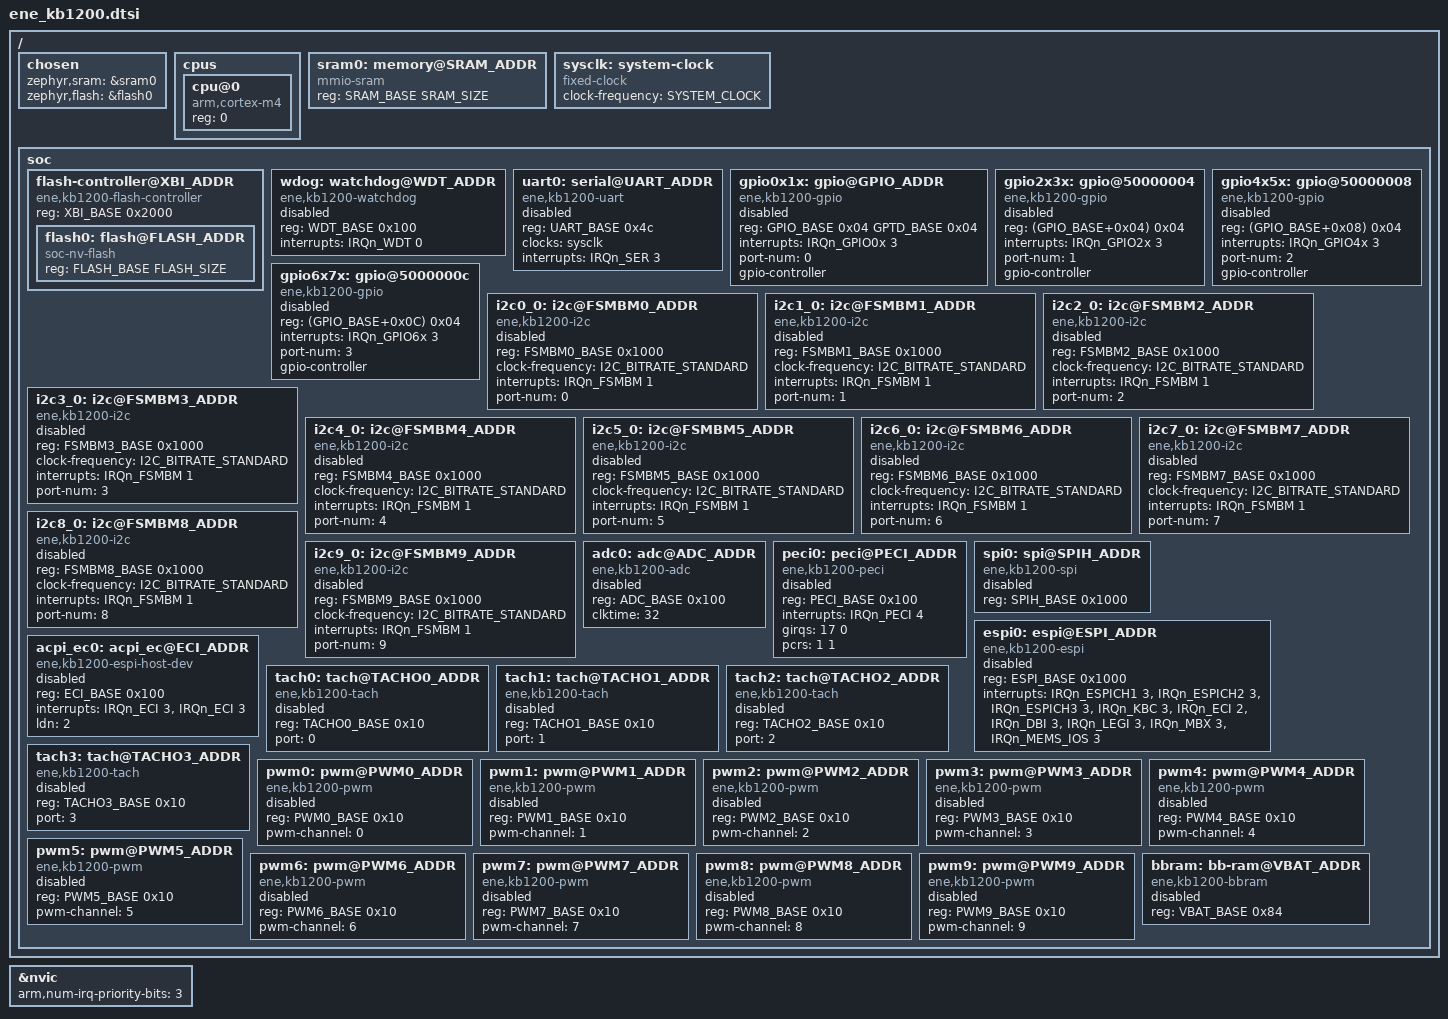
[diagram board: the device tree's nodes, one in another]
/* SPDX-License-Identifier: Apache-2.0 */

#include <arm/armv7-m.dtsi>
#include <dt-bindings/gpio/gpio.h>
#include <dt-bindings/i2c/i2c.h>
#include "kb1200_dtsi.h"

/ {

	chosen {
		zephyr,sram = &sram0;
		zephyr,flash = &flash0;
	};

	cpus {
		#address-cells = <1>;
		#size-cells = <0>;

		cpu@0 {
			device_type = "cpu";
			compatible = "arm,cortex-m4";
			reg = <0>;
		};
	};

	sram0: memory@SRAM_ADDR {
		compatible = "mmio-sram";
		reg = <SRAM_BASE SRAM_SIZE>;
	};

	sysclk: system-clock {
		compatible = "fixed-clock";
		clock-frequency = <SYSTEM_CLOCK>;
		#clock-cells = <0>;
	};

	soc {

		flash-controller@XBI_ADDR {
			compatible = "ene,kb1200-flash-controller";
			reg = <XBI_BASE 0x2000>;
			#address-cells = <1>;
			#size-cells = <1>;

			flash0: flash@FLASH_ADDR {
				compatible = "soc-nv-flash";
				reg = <FLASH_BASE FLASH_SIZE>;
			};
		};

		wdog: watchdog@WDT_ADDR {
			compatible = "ene,kb1200-watchdog";
			reg = <WDT_BASE 0x100>;
			interrupts = <IRQn_WDT 0>;   // 16-16
			status = "disabled";
		};

		uart0: serial@UART_ADDR {
			compatible = "ene,kb1200-uart";
			reg = <UART_BASE 0x4c>;
			clocks = <&sysclk>;
			interrupts = <IRQn_SER 3>;  // 37-16
			status = "disabled";
		};

		gpio0x1x: gpio@GPIO_ADDR {
			compatible = "ene,kb1200-gpio";
			reg = <GPIO_BASE 0x04
			       GPTD_BASE 0x04>;
			reg-names = "gpio1x", "gptd1x";
			interrupts = <IRQn_GPIO0x 3>;   // 18-16
			port-num = <0>;
			gpio-controller;
			#gpio-cells = <2>;
			status = "disabled";
		};
		gpio2x3x: gpio@50000004 {
			compatible = "ene,kb1200-gpio";
			reg = <(GPIO_BASE+0x04) 0x04>;
			interrupts = <IRQn_GPIO2x 3>;   // 20-16
			port-num = <1>;
			gpio-controller;
			#gpio-cells = <2>;
			status = "disabled";
		};
		gpio4x5x: gpio@50000008 {
			compatible = "ene,kb1200-gpio";
			reg = <(GPIO_BASE+0x08) 0x04>;
			interrupts = <IRQn_GPIO4x 3>;   // 22-16
			port-num = <2>;
			gpio-controller;
			#gpio-cells = <2>;
			status = "disabled";
		};
		gpio6x7x: gpio@5000000c {
			compatible = "ene,kb1200-gpio";
			reg = <(GPIO_BASE+0x0C) 0x04>;
			interrupts = <IRQn_GPIO6x 3>;   // 24-16
			port-num = <3>;
			gpio-controller;
			#gpio-cells = <2>;
			status = "disabled";
		};

		i2c0_0: i2c@FSMBM0_ADDR {
			compatible = "ene,kb1200-i2c";
			reg = <FSMBM0_BASE 0x1000>;
			clock-frequency = <I2C_BITRATE_STANDARD>;
			interrupts = <IRQn_FSMBM 1>;  // 31-16
			#address-cells = <1>;
			#size-cells = <0>;
			port-num = <0>;
			status = "disabled";
		};
		i2c1_0: i2c@FSMBM1_ADDR {
			compatible = "ene,kb1200-i2c";
			reg = <FSMBM1_BASE 0x1000>;
			clock-frequency = <I2C_BITRATE_STANDARD>;
			interrupts = <IRQn_FSMBM 1>;  // 31-16
			#address-cells = <1>;
			#size-cells = <0>;
			port-num = <1>;
			status = "disabled";
		};
		i2c2_0: i2c@FSMBM2_ADDR {
			compatible = "ene,kb1200-i2c";
			reg = <FSMBM2_BASE 0x1000>;
			clock-frequency = <I2C_BITRATE_STANDARD>;
			interrupts = <IRQn_FSMBM 1>;  // 31-16
			#address-cells = <1>;
			#size-cells = <0>;
			port-num = <2>;
			status = "disabled";
		};
		i2c3_0: i2c@FSMBM3_ADDR {
			compatible = "ene,kb1200-i2c";
			reg = <FSMBM3_BASE 0x1000>;
			clock-frequency = <I2C_BITRATE_STANDARD>;
			interrupts = <IRQn_FSMBM 1>;  // 31-16
			#address-cells = <1>;
			#size-cells = <0>;
			port-num = <3>;
			status = "disabled";
		};
		i2c4_0: i2c@FSMBM4_ADDR {
			compatible = "ene,kb1200-i2c";
			reg = <FSMBM4_BASE 0x1000>;
			clock-frequency = <I2C_BITRATE_STANDARD>;
			interrupts = <IRQn_FSMBM 1>;  // 31-16
			#address-cells = <1>;
			#size-cells = <0>;
			port-num = <4>;
			status = "disabled";
		};
		i2c5_0: i2c@FSMBM5_ADDR {
			compatible = "ene,kb1200-i2c";
			reg = <FSMBM5_BASE 0x1000>;
			clock-frequency = <I2C_BITRATE_STANDARD>;
			interrupts = <IRQn_FSMBM 1>;  // 31-16
			#address-cells = <1>;
			#size-cells = <0>;
			port-num = <5>;
			status = "disabled";
		};
		i2c6_0: i2c@FSMBM6_ADDR {
			compatible = "ene,kb1200-i2c";
			reg = <FSMBM6_BASE 0x1000>;
			clock-frequency = <I2C_BITRATE_STANDARD>;
			interrupts = <IRQn_FSMBM 1>;  // 31-16
			#address-cells = <1>;
			#size-cells = <0>;
			port-num = <6>;
			status = "disabled";
		};
		i2c7_0: i2c@FSMBM7_ADDR {
			compatible = "ene,kb1200-i2c";
			reg = <FSMBM7_BASE 0x1000>;
			clock-frequency = <I2C_BITRATE_STANDARD>;
			interrupts = <IRQn_FSMBM 1>;  // 31-16
			#address-cells = <1>;
			#size-cells = <0>;
			port-num = <7>;
			status = "disabled";
		};
		i2c8_0: i2c@FSMBM8_ADDR {
			compatible = "ene,kb1200-i2c";
			reg = <FSMBM8_BASE 0x1000>;
			clock-frequency = <I2C_BITRATE_STANDARD>;
			interrupts = <IRQn_FSMBM 1>;  // 31-16
			#address-cells = <1>;
			#size-cells = <0>;
			port-num = <8>;
			status = "disabled";
		};
		i2c9_0: i2c@FSMBM9_ADDR {
			compatible = "ene,kb1200-i2c";
			reg = <FSMBM9_BASE 0x1000>;
			clock-frequency = <I2C_BITRATE_STANDARD>;
			interrupts = <IRQn_FSMBM 1>;  // 31-16
			#address-cells = <1>;
			#size-cells = <0>;
			port-num = <9>;
			status = "disabled";
		};

		adc0: adc@ADC_ADDR {
			compatible = "ene,kb1200-adc";
			reg = <ADC_BASE 0x100>;
			status = "disabled";
			#io-channel-cells = <1>;
			clktime = <32>;
		};

		peci0: peci@PECI_ADDR {
			compatible = "ene,kb1200-peci";
			reg = <PECI_BASE 0x100>;
			interrupts = <IRQn_PECI 4>;  // 36-16
			girqs = <17 0>;
			pcrs = <1 1>;
			#address-cells = <1>;
			#size-cells = <0>;
			status = "disabled";
		};

		spi0: spi@SPIH_ADDR {
			compatible = "ene,kb1200-spi";
			#address-cells = <1>;
			#size-cells = <0>;
			reg = <SPIH_BASE 0x1000>;
			status = "disabled";
		};

		espi0: espi@ESPI_ADDR {
			compatible = "ene,kb1200-espi";
			reg = <ESPI_BASE 0x1000>;
			interrupts = <IRQn_ESPICH1 3>,   // 46-16
			             <IRQn_ESPICH2 3>,
			             <IRQn_ESPICH3 3>,
			             <IRQn_KBC 3>,       // 40-16
			             <IRQn_ECI 2>,
			             <IRQn_DBI 3>,
			             <IRQn_LEGI 3>,
			             <IRQn_MBX 3>,
			             <IRQn_MEMS_IOS 3>;
			interrupt-names = "vwire", "oob", "flash", "kbc", "eci", "dbi", "legi", "mbx", "memio";
			#address-cells = <1>;
			#size-cells = <0>;
			status = "disabled";
		};

		acpi_ec0: acpi_ec@ECI_ADDR {
			compatible = "ene,kb1200-espi-host-dev";
			reg = <ECI_BASE 0x100>;
			interrupts = <IRQn_ECI 3>, <IRQn_ECI 3>;
			interrupt-names = "acpi_ibf", "acpi_obe";
			ldn = <2>;
			status = "disabled";
		};

		tach0: tach@TACHO0_ADDR {
			compatible = "ene,kb1200-tach";
			reg = <TACHO0_BASE 0x10>;
			port = <0>;
			status = "disabled";
		};
		tach1: tach@TACHO1_ADDR {
			compatible = "ene,kb1200-tach";
			reg = <TACHO1_BASE 0x10>;
			port = <1>;
			status = "disabled";
		};
		tach2: tach@TACHO2_ADDR {
			compatible = "ene,kb1200-tach";
			reg = <TACHO2_BASE 0x10>;
			port = <2>;
			status = "disabled";
		};
		tach3: tach@TACHO3_ADDR {
			compatible = "ene,kb1200-tach";
			reg = <TACHO3_BASE 0x10>;
			port = <3>;
			status = "disabled";
		};

		pwm0: pwm@PWM0_ADDR {
			compatible = "ene,kb1200-pwm";
			reg = <PWM0_BASE 0x10>;
			pwm-channel = <0>;
			#pwm-cells = <3>;
			status = "disabled";
		};
		pwm1: pwm@PWM1_ADDR {
			compatible = "ene,kb1200-pwm";
			reg = <PWM1_BASE 0x10>;
			pwm-channel = <1>;
			#pwm-cells = <3>;
			status = "disabled";
		};
		pwm2: pwm@PWM2_ADDR {
			compatible = "ene,kb1200-pwm";
			reg = <PWM2_BASE 0x10>;
			pwm-channel = <2>;
			#pwm-cells = <3>;
			status = "disabled";
		};
		pwm3: pwm@PWM3_ADDR {
			compatible = "ene,kb1200-pwm";
			reg = <PWM3_BASE 0x10>;
			pwm-channel = <3>;
			#pwm-cells = <3>;
			status = "disabled";
		};
		pwm4: pwm@PWM4_ADDR {
			compatible = "ene,kb1200-pwm";
			reg = <PWM4_BASE 0x10>;
			pwm-channel = <4>;
			#pwm-cells = <3>;
			status = "disabled";
		};
		pwm5: pwm@PWM5_ADDR {
			compatible = "ene,kb1200-pwm";
			reg = <PWM5_BASE 0x10>;
			pwm-channel = <5>;
			#pwm-cells = <3>;
			status = "disabled";
		};
		pwm6: pwm@PWM6_ADDR {
			compatible = "ene,kb1200-pwm";
			reg = <PWM6_BASE 0x10>;
			pwm-channel = <6>;
			#pwm-cells = <3>;
			status = "disabled";
		};
		pwm7: pwm@PWM7_ADDR {
			compatible = "ene,kb1200-pwm";
			reg = <PWM7_BASE 0x10>;
			pwm-channel = <7>;
			#pwm-cells = <3>;
			status = "disabled";
		};
		pwm8: pwm@PWM8_ADDR {
			compatible = "ene,kb1200-pwm";
			reg = <PWM8_BASE 0x10>;
			pwm-channel = <8>;
			#pwm-cells = <3>;
			status = "disabled";
		};
		pwm9: pwm@PWM9_ADDR {
			compatible = "ene,kb1200-pwm";
			reg = <PWM9_BASE 0x10>;
			pwm-channel = <9>;
			#pwm-cells = <3>;
			status = "disabled";
		};
		bbram: bb-ram@VBAT_ADDR {
			compatible = "ene,kb1200-bbram";
			reg = <VBAT_BASE 0x84>;
			status = "disabled";
		};

	};
};

&nvic {
	arm,num-irq-priority-bits = <3>;
};
